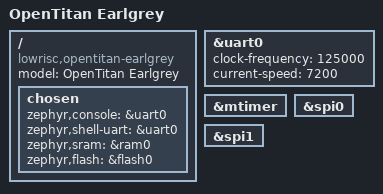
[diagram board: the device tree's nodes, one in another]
/*
 * Copyright (c) 2023 by Rivos Inc.
 *
 * SPDX-License-Identifier: Apache-2.0
 */

/dts-v1/;

#include <lowrisc/opentitan_earlgrey.dtsi>

/ {
	model = "OpenTitan Earlgrey";
	compatible = "lowrisc,opentitan-earlgrey";

	chosen {
		zephyr,console = &uart0;
		zephyr,shell-uart = &uart0;
		zephyr,sram = &ram0;
		zephyr,flash = &flash0;
	};
};

&uart0 {
	status = "okay";
	clock-frequency = <125000>;
	current-speed = <7200>;
};

&mtimer {
	status = "okay";
};

&spi0 {
	status = "okay";
};

&spi1 {
	status = "okay";
};
